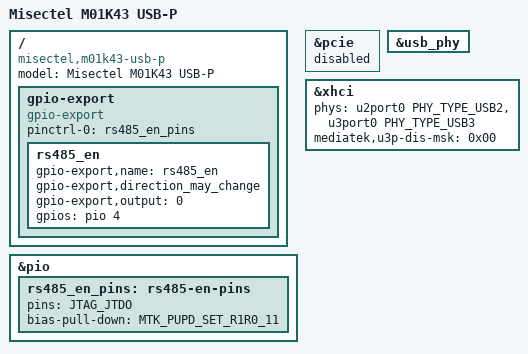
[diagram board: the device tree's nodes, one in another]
// SPDX-License-Identifier: GPL-2.0-or-later OR MIT
/dts-v1/;

#include "mt7981b-misectel-m01k43-p.dts"

/ {
	model = "Misectel M01K43 USB-P";
	compatible = "misectel,m01k43-usb-p", "misectel,m01k43", "mediatek,mt7981";

	gpio-export {
		compatible = "gpio-export";
		pinctrl-names = "default";
		pinctrl-0 = <&rs485_en_pins>;

		rs485_en {
			gpio-export,name = "rs485_en";
			gpio-export,direction_may_change;
			gpio-export,output = <0>;
			gpios = <&pio 4 GPIO_ACTIVE_HIGH>;
		};
	};
};

&pio {
	rs485_en_pins: rs485-en-pins {
		pins = "JTAG_JTDO";
		bias-pull-down = <MTK_PUPD_SET_R1R0_11>;
	};
};

&pcie {
	status = "disabled";
};

&usb_phy {
	status = "okay";
};

&xhci {
	phys = <&u2port0 PHY_TYPE_USB2>, <&u3port0 PHY_TYPE_USB3>;
	mediatek,u3p-dis-msk = <0x00>;
	status = "okay";
};
